# AE302F80F55D5LE_CM55_HE_View register map
Vendor: Alif Semiconductor; Series: E3; File version: 1.0
CPU: CM55 r1p0, selectable endian, MPU, FPU, double-precision FPU, DSP, VTOR, 8 interrupt priority bits, 1 SAU regions
Registers are 32-bit, read-write, reset 0x0 unless marked. A register's access mark holds for its fields unless they carry their own. Offsets are from the block's base; [hi:lo] are bit positions; 'fields as' and 'values as' point back to an identical list.

## SDMMC (part 2 of 2)
Base 0x48102000
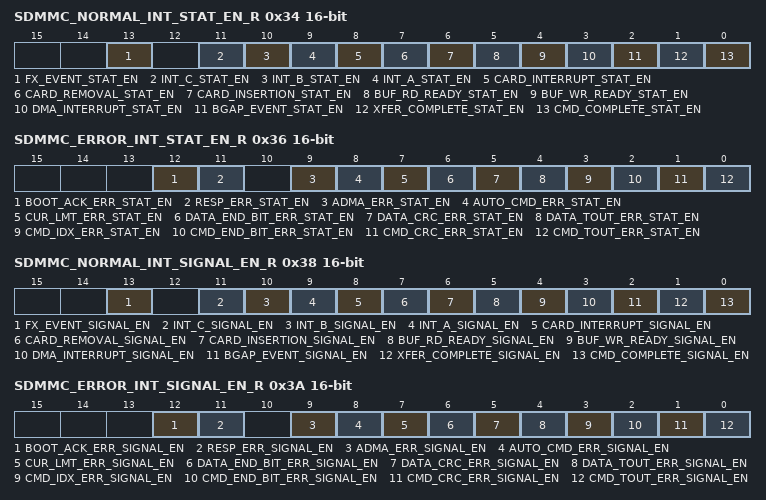
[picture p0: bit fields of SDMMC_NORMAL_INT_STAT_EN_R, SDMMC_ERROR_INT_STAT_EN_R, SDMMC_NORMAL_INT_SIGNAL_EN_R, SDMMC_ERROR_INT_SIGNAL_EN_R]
0x34 SDMMC_NORMAL_INT_STAT_EN_R 16-bit — Normal Interrupt Status Enable Register
  [all] fields
    0=Masked; 1=Enabled
  [13] FX_EVENT_STAT_EN — FX Event Status Enable. This bit is added from Version 4.10.
  [11] INT_C_STAT_EN — INT_C (Embedded) Status Enable. If this bit is set to 0x0, the Host Controller clears the interrupt request to the System. The Host Driver may clear this bit before servicing the INT_C and may set this bit again after all interrupt requests to INT_C pin are cleared to prevent inadvertent interrupts.
  [10] INT_B_STAT_EN — INT_B (Embedded) Status Enable. If this bit is set to 0x0, the Host Controller clears the interrupt request to the System. The Host Driver may clear this bit before servicing the INT_B and may set this bit again after all interrupt requests to INT_B pin are cleared to prevent inadvertent interrupts.
  [9] INT_A_STAT_EN — INT_A (Embedded) Status Enable. If this bit is set to 0x0, the Host Controller clears the interrupt request to the System. The Host Driver may clear this bit before servicing the INT_A and may set this bit again after all interrupt requests to INT_A pin are cleared to prevent inadvertent interrupts.
  [8] CARD_INTERRUPT_STAT_EN — Card Interrupt Status Enable. If this bit is set to 0x0, the Host Controller clears the interrupt request to the System. The Card Interrupt detection is stopped when this bit is cleared and restarted when this bit is set to 0x1. The Host Driver may clear the Card Interrupt Status Enable before servicing the Card Interrupt and may set this bit again after all interrupt requests from the card are cleared to prevent inadvertent interrupts. By setting this bit to 0x0, interrupt input must be masked by implementation so that the interrupt input is not affected by external signal in any state (for example: floating).
  [7] CARD_REMOVAL_STAT_EN — Card Removal Status Enable.
  [6] CARD_INSERTION_STAT_EN — Card Insertion Status Enable.
  [5] BUF_RD_READY_STAT_EN — Buffer Read Ready Status Enable.
  [4] BUF_WR_READY_STAT_EN — Buffer Write Ready Status Enable.
  [3] DMA_INTERRUPT_STAT_EN — DMA Interrupt Status Enable.
  [2] BGAP_EVENT_STAT_EN — Block Gap Event Status Enable.
  [1] XFER_COMPLETE_STAT_EN — Transfer Complete Status Enable.
  [0] CMD_COMPLETE_STAT_EN — Command Complete Status Enable.
0x36 SDMMC_ERROR_INT_STAT_EN_R 16-bit — Error Interrupt Status Enable Register
  [all] fields
    0=Masked; 1=Enabled
  [12] BOOT_ACK_ERR_STAT_EN — Boot Acknowledgment Error (eMMC mode only). Setting this bit to 0x1 enables setting of Boot Acknowledgment Error in the SDMMC_ERROR_INT_STAT_R register.
  [11] RESP_ERR_STAT_EN — Response Error Status Enable (SD mode only).
  [9] ADMA_ERR_STAT_EN — ADMA Error Status Enable.
  [8] AUTO_CMD_ERR_STAT_EN — Auto CMD Error Status Enable (SD or eMMC mode only).
  [7] CUR_LMT_ERR_STAT_EN — Current Limit Error Status Enable.
  [6] DATA_END_BIT_ERR_STAT_EN — Data End Bit Error Status Enable (SD or eMMC mode only).
  [5] DATA_CRC_ERR_STAT_EN — Data CRC Error Status Enable (SD or eMMC mode only).
  [4] DATA_TOUT_ERR_STAT_EN — Data Timeout Error Status Enable (SD or eMMC mode only).
  [3] CMD_IDX_ERR_STAT_EN — Command Index Error Status Enable (SD or eMMC mode only).
  [2] CMD_END_BIT_ERR_STAT_EN — Command End Bit Error Status Enable (SD or eMMC mode only).
  [1] CMD_CRC_ERR_STAT_EN — Command CRC Error Status Enable (SD or eMMC mode only).
  [0] CMD_TOUT_ERR_STAT_EN — Command Timeout Error Status Enable (SD or eMMC mode only).
0x38 SDMMC_NORMAL_INT_SIGNAL_EN_R 16-bit — Normal Interrupt Signal Enable Register
  [all] fields
    0=Masked; 1=Enabled
  [13] FX_EVENT_SIGNAL_EN — FX Event Signal Enable.
  [11] INT_C_SIGNAL_EN — INT_C (Embedded) Signal Enable.
  [10] INT_B_SIGNAL_EN — INT_B (Embedded) Signal Enable.
  [9] INT_A_SIGNAL_EN — INT_A (Embedded) Signal Enable.
  [8] CARD_INTERRUPT_SIGNAL_EN — Card Interrupt Signal Enable.
  [7] CARD_REMOVAL_SIGNAL_EN — Card Removal Signal Enable.
  [6] CARD_INSERTION_SIGNAL_EN — Card Insertion Signal Enable.
  [5] BUF_RD_READY_SIGNAL_EN — Buffer Read Ready Signal Enable.
  [4] BUF_WR_READY_SIGNAL_EN — Buffer Write Ready Signal Enable.
  [3] DMA_INTERRUPT_SIGNAL_EN — DMA Interrupt Signal Enable.
  [2] BGAP_EVENT_SIGNAL_EN — Block Gap Event Signal Enable.
  [1] XFER_COMPLETE_SIGNAL_EN — Transfer Complete Signal Enable.
  [0] CMD_COMPLETE_SIGNAL_EN — Command Complete Signal Enable.
0x3A SDMMC_ERROR_INT_SIGNAL_EN_R 16-bit — Error Interrupt Signal Enable Register
  [12] BOOT_ACK_ERR_SIGNAL_EN — Boot Acknowledgment Error (eMMC mode only). Setting this bit to 0x1 enables generating interrupt signal when Boot Acknowledgement Error in the SDMMC_ERROR_INT_STAT_R register is set.
    0=Masked; 1=Enabled
  [11] RESP_ERR_SIGNAL_EN — Response Error Signal Enable (SD mode only).
    0=Masked; 1=Enabled
  [9] ADMA_ERR_SIGNAL_EN — ADMA Error Signal Enable.
    0=Masked; 1=Enabled
  [8] AUTO_CMD_ERR_SIGNAL_EN — Auto CMD Error Signal Enable (SD or eMMC mode only).
    0=Masked; 1=Enabled
  [7] CUR_LMT_ERR_SIGNAL_EN — Current Limit Error Signal Enable.
    0=Masked; 1=Enabled
  [6] DATA_END_BIT_ERR_SIGNAL_EN — Data End Bit Error Signal Enable (SD or eMMC mode only).
    0=Masked; 1=Enabled
  [5] DATA_CRC_ERR_SIGNAL_EN — Data CRC Error Signal Enable (SD or eMMC mode only).
    0=Masked; 1=Enabled
  [4] DATA_TOUT_ERR_SIGNAL_EN — Data Timeout Error Signal Enable (SD or eMMC mode only).
    0=Masked; 1=Enabled
  [3] CMD_IDX_ERR_SIGNAL_EN — Command Index Error Signal Enable (SD or eMMC mode only).
    0=No error; 1=Error
  [2] CMD_END_BIT_ERR_SIGNAL_EN — Command End Bit Error Signal Enable (SD or eMMC mode only).
    0=Masked; 1=Enabled
  [1] CMD_CRC_ERR_SIGNAL_EN — Command CRC Error Signal Enable (SD or eMMC mode only).
    0=Masked; 1=Enabled
  [0] CMD_TOUT_ERR_SIGNAL_EN — Command Timeout Error Signal Enable (SD or eMMC mode only).
    0=Masked; 1=Enabled
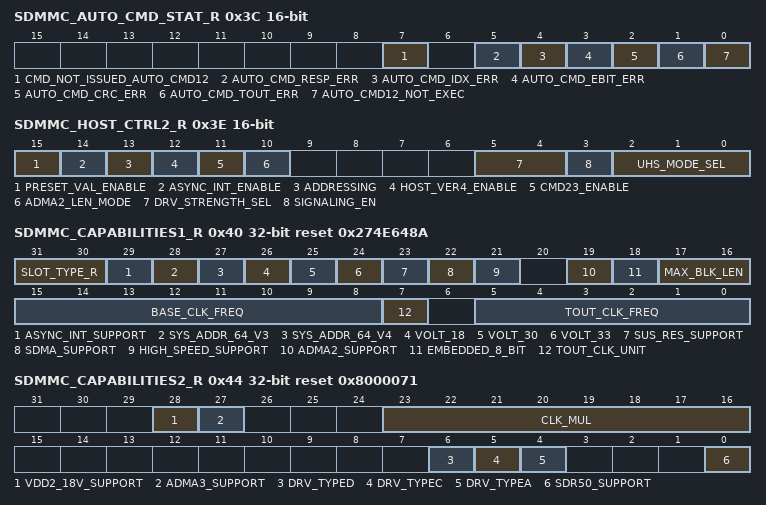
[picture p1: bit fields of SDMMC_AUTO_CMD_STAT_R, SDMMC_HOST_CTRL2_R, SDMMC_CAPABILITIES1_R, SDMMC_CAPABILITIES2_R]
0x3C SDMMC_AUTO_CMD_STAT_R 16-bit ro — Auto CMD Status Register
  [7] CMD_NOT_ISSUED_AUTO_CMD12 — Command Not Issued By Auto CMD12 Error. This bit is set to 0x0 when Auto CMD Error is generated by Auto CMD23.
    0=No error; 1=Not issued
  [5] AUTO_CMD_RESP_ERR — Auto CMD Response Error. This bit is set when the SDMMC_XFER_MODE_R[RESP_ERR_CHK_ENABLE] bit is set to 0x1 and an error is detected in R1 response of either Auto CMD12 or CMD13. This status is ignored if any bit between D00 to D04 is set to 0x1.
    0=No error; 1=Error
  [4] AUTO_CMD_IDX_ERR — Auto CMD Index Error. This bit is set if the command index error occurs in response to a command.
    0=No error; 1=Error
  [3] AUTO_CMD_EBIT_ERR — Auto CMD End Bit Error. This bit is set when detecting that the end bit of command response is 0x0.
    0=No error; 1=End bit error generated
  [2] AUTO_CMD_CRC_ERR — Auto CMD CRC Error. This bit is set when detecting a CRC error in the command response.
    0=No Error; 1=CRC Error Generated
  [1] AUTO_CMD_TOUT_ERR — Auto CMD Timeout Error. This bit is set if no response is returned with 64 SD_CLK cycles from the end bit of the command. If this bit is set to 0x1, error status bits (D04 to D01) are meaningless.
    0=No error; 1=Time out
  [0] AUTO_CMD12_NOT_EXEC — Auto CMD12 Not Executed. If multiple memory block data transfer is not started due to a command error, this bit is not set because it is not necessary to issue an Auto CMD12. Setting this bit to 0x1 means that the Host Controller cannot issue Auto CMD12 to stop multiple memory block data transfer, due to some error. If this bit is set to 0x1, error status bits (D04 to D01) is meaningless. This bit is set to 0x0 when Auto CMD Error is generated by Auto CMD23.
    0=Executed; 1=Not executed
0x3E SDMMC_HOST_CTRL2_R 16-bit — Host Control 2 Register
  [15] PRESET_VAL_ENABLE — Preset Value Enable. This bit enables automatic selection of SD_CLK frequency and Driver strength in Preset Value registers. When this bit is set, SD_CLK frequency generation (SDMMC_CLK_CTRL_R[CLK_GEN_SELECT], the SDMMC_CLK_CTRL_R[FREQ_SEL]), and the driver strength selection are performed by the Host Controller. These values are selected from set of Preset Value registers based on selected speed mode.
    0=SD_CLK and driver strength are controlled by Host Driver; 1=Automatic selection by preset value are enabled
  [14] ASYNC_INT_ENABLE — Asynchronous Interrupt Enable. This bit can be set if a card supports asynchronous interrupts and this bit is set to 0x1 in the Capabilities registers (SDMMC_CAPABILITIES1_R and SDMMC_CAPABILITIES2_R).
    0=Disabled; 1=Enabled
  [13] ADDRESSING — 64-bit Addressing. This bit is effective when the HOST_VER4_ENABLE bit is set to 0x1.
    0=32 bits addressing; 1=64 bits addressing
  [12] HOST_VER4_ENABLE — Host Version 4 Enable. This bit selects either Version 3.00 compatible mode or Version 4 mode. Functions of following fields are modified for Host Version 4 mode: - SDMA Address: SDMA uses the SDMMC_ADMA_SA_LOW_R register (0x58 - 0x5F) instead of the SDMMC_SDMASA_R register (0x0 - 0x3). - ADMA2/ADMA3 selection: ADMA3 is selected by the SDMMC_HOST_CTRL1_R[DMA_SEL] bit field. - 64-bit ADMA Descriptor Size: 128-bit descriptor is used instead of 96-bit descriptor when 64-bit Addressing is set to 0x1. - Selection of 32-bit/64-bit System Addressing: Either 32-bit or 64-bit system addressing is selected by 64-bit Addressing bit in this register. - 32-bit Block Count: The SDMMC_SDMASA_R register (0x0 - 0x3) is modified to 32-bit Block Count Register Note: It is recommended not to program ADMA3 Integrated Descriptor Address registers, while operating in Host version less than 4 mode (HOST_VER4_ENABLE = 0x0).
    0=Version 3.00 compatible mode; 1=Version 4 mode
  [11] CMD23_ENABLE — CMD23 Enable. If the card supports CMD23, this bit is set to 0x1. This bit is used to select Auto CMD23 or Auto CMD12 for ADMA3 data transfer.
    0=Auto CMD23 is disabled; 1=Auto CMD23 is enabled
  [10] ADMA2_LEN_MODE — ADMA2 Length Mode. This bit selects ADMA2 Length mode to be either 16-bit or 26-bit.
    0=16-bit Data Length mode; 1=26-bit Data Length mode
  [5:4] DRV_STRENGTH_SEL — Driver Strength Select. This bit is used to select the Host Controller output driver in 1.8 V signaling UHS-I or eMMC speed modes. The bit depends on setting of the PRESET_VAL_ENABLE bit.
    0=Driver TYPEB is selected; 1=Driver TYPEA is selected; 2=Driver TYPEC is selected; 3=Driver TYPED is selected
  [3] SIGNALING_EN — 1.8 V Signaling Enable. This bit controls voltage regulator for I/O cell in UHS-I or eMMC speed modes. Setting this bit from 0x0 to 0x1 starts changing the signal voltage from 3.3 V to 1.8 V. The Host Controller clears this bit if switching to 1.8 signaling fails. Note: This bit must be set for all UHS-I speed modes (SDR12/SDR25/SDR50).
    0=3.3 V signalling; 1=1.8 V signalling
  [2:0] UHS_MODE_SEL — UHS Mode or eMMC Speed Mode Select. These bits are used to select UHS mode in the SD mode of operation. In eMMC mode, these bits are used to select eMMC speed mode. UHS mode (SD mode only):
    0=SDR12; 1=SDR25; 2=SDR50
0x40 SDMMC_CAPABILITIES1_R ro reset 0x274E648A — Capabilities 1 Register (0 to 31)
  [31:30] SLOT_TYPE_R — Slot Type. These bits indicate usage of a slot by a specific Host System.
    0=Removable card slot; 1=Embedded slot for one device; 2=Shared bus slot (SD mode)
  [29] ASYNC_INT_SUPPORT — Asynchronous Interrupt Support (SD mode only).
    0=Asynchronous interrupt not supported; 1=Asynchronous interrupt supported
  [28] SYS_ADDR_64_V3 — 64-bit System Address Support for V3. This bit sets the Host controller to support 64-bit System Addressing of V3 mode. SDMA cannot be used in 64-bit Addressing in Version 3 Mode. If this bit is set to 0x1, 64-bit ADMA2 with using 96-bit Descriptor can be enabled by setting the SDMMC_HOST_CTRL2_R[HOST_VER4_ENABLE] bit to 0x0 and SDMMC_HOST_CTRL1_R[DMA_SEL] bit field to 0x3.
    0=64-bit System address for V3 not supported; 1=64-bit System address for V3 supported
  [27] SYS_ADDR_64_V4 — 64-bit System Address Support for V4. This bit sets the Host Controller to support 64-bit System Addressing of V4 mode. When this bit is set to 0x1, full or part of 64-bit address must be used to decode the Host Controller registers so that Host Controller registers can be placed above system memory area. 64-bit address decode of Host Controller registers is effective regardless of setting to 64-bit Addressing in the SDMMC_HOST_CTRL2_R register. If this bit is set to 0x1, 64-bit DMA Addressing for version 4 is enabled by setting the SDMMC_HOST_CTRL2_R[HOST_VER4_ENABLE] and SDMMC_HOST_CTRL2_R[ADDRESSING] bits to 0x1, SDMA can be used and ADMA2 uses 128-bit Descriptor.
    0=64-bit System address for V4 not supported; 1=64-bit System address for V4 supported
  [26] VOLT_18 — Voltage Support for 1.8 V.
    0=1.8 V not supported; 1=1.8 V supported
  [25] VOLT_30 — Voltage Support for SD 3.0 V or Embedded 1.2 V.
    0=SD 3.0 V or embedded 1.2 V not supported; 1=SD 3.0 V or embedded supported
  [24] VOLT_33 — Voltage Support for 3.3 V.
    0=3.3 V not supported; 1=3.3 V supported
  [23] SUS_RES_SUPPORT — Suspense/Resume Support. This bit indicates whether the Host Controller supports Suspend/Resume functionality. If this bit is 0x0, the Host Driver does not issue either Suspend or Resume commands because the Suspend and Resume mechanism is not supported.
    0=Not supported; 1=Supported
  [22] SDMA_SUPPORT — SDMA Support. This bit indicates whether the Host Controller is capable of using SDMA to transfer data between the system memory and the Host Controller directly.
    0=SDMA not supported; 1=SDMA supported
  [21] HIGH_SPEED_SUPPORT — High Speed Support. This bit indicates whether the Host Controller and the Host System supports High Speed mode and they can supply the SD Clock frequency from 25 MHz to 50 MHz.
    0=High speed not supported; 1=High speed supported
  [19] ADMA2_SUPPORT — ADMA2 Support. This bit indicates whether the Host Controller is capable of using ADMA2.
    0=ADMA2 not supported; 1=ADMA2 supported
  [18] EMBEDDED_8_BIT — 8-bit Support for Embedded Device. This bit indicates whether the Host Controller is capable of using an 8-bit bus width mode. This bit is not effective when the SLOT_TYPE_R bit is set to 0x2.
    0=8-bit bus width not supported; 1=8-bit bus width supported
  [17:16] MAX_BLK_LEN — Maximum Block Length. This bit indicates the maximum block size that the Host Driver can read and write to the buffer in the Host Controller. The buffer transfers this block size without wait cycles. The transfer block length is always 512 Bytes for the SD Memory irrespective of this bit.
    0=512 Bytes; 1=1024 Bytes; 2=2048 Bytes
  [15:8] BASE_CLK_FREQ — Base Clock Frequency for SD Clock. These bits indicate the base (maximum) clock frequency for the SD Clock. The definition of these bits depend on the Host Controller Version. 6-Bit Base Clock Frequency: This mode is supported by the Host Controller version 1.00 and 2.00. The upper 2 bits are not effective and are always 0x0. The unit values are 1 MHz. The supported clock range is 10 MHz to 63 MHz. 0x0: Get information through another method 0x1: 1 MHz 0x2: 2 MHz ... 0x3F: 63 MHz 0x40 - 0xFF: Not supported 8-Bit Base Clock Frequency: This mode is supported by the Host Controller version 3.00. The unit values are 1 MHz. The supported clock range is 10 MHz to 255 MHz. 0x0: Get information through another method 0x1: MHz 0x2: 2 MHz ... 0xFF: 255 MHz
  [7] TOUT_CLK_UNIT — Timeout Clock Unit. This bit shows the unit of base clock frequency used to detect Data Timeout Error.
    0=kHz; 1=MHz
  [5:0] TOUT_CLK_FREQ — Timeout Clock Frequency. This bit shows the base clock frequency used to detect Data Timeout Error. The Timeout Clock unit defines the unit of timeout clock frequency. It can be kHz or MHz.
    0=Get information through another method; 1=1 kHz / 1 MHz; 2=2 kHz / 2 MHz; 3=3 kHz / 3 MHz; 63=63 kHz / 63 MHz
0x44 SDMMC_CAPABILITIES2_R ro reset 0x8000071 — Capabilities 2 Register (32 to 63)
  [28] VDD2_18V_SUPPORT — 1.8 V VDD2 Support. This bit indicates support of VDD2 for the Host System.
    0=1.8 V VDD2 not supported; 1=1.8 V VDD2 supported
  [27] ADMA3_SUPPORT — ADMA3 Support. This bit indicates whether the Host Controller is capable of using ADMA3.
    0=ADMA3 not supported; 1=ADMA3 supported
  [23:16] CLK_MUL — Clock Multiplier. These bits indicate the clock multiplier of the programmable clock generator. Setting these bits to 0x0 means that the Host Controller does not support a programmable clock generator.
    0=Clock multiplier not supported; 1=Clock multiplier M = 2; 2=Clock multiplier M = 3; 255=Clock multiplier M = 256
  [6] DRV_TYPED — Driver Type D Support (UHS-I Only). This bit indicates support of Driver Type D for 1.8 V Signaling.
    0=Driver Type D not supported; 1=Driver Type D supported
  [5] DRV_TYPEC — Driver Type C Support (UHS-I Only). This bit indicates support of Driver Type C for 1.8 V Signaling.
    0=Driver Type C not supported; 1=Driver Type C supported
  [4] DRV_TYPEA — Driver Type A Support (UHS-I Only). This bit indicates support of Driver Type A for 1.8 V Signaling.
    0=Driver Type A not supported; 1=Driver Type A supported
  [0] SDR50_SUPPORT — SDR50 Support (UHS-I Only). This bit indicates that SDR50 is supported.
    0=SDR50 not supported; 1=SDR50 supported
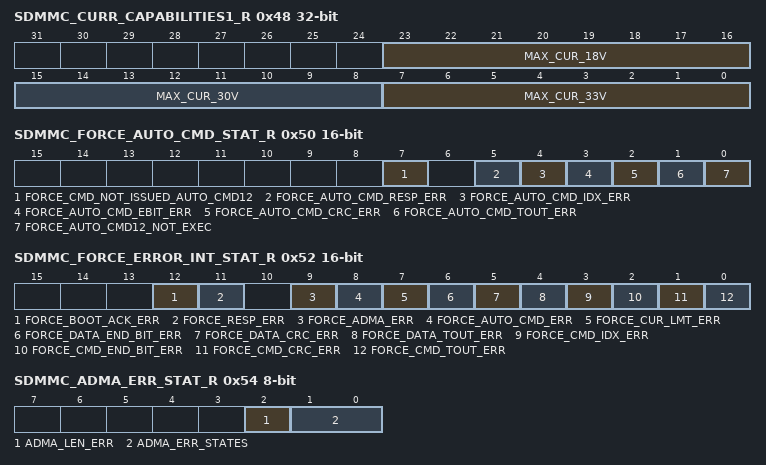
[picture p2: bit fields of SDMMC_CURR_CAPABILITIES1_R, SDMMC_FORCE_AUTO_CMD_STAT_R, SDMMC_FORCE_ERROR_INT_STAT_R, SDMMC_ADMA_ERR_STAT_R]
0x48 SDMMC_CURR_CAPABILITIES1_R ro — Maximum Current Capabilities 1 Register (0 to 31)
  [all] fields
    0=Get information through another method; 1=4 mA; 2=8 mA; 3=13 mA
  [23:16] MAX_CUR_18V — Maximum Current for 1.8 V. This bit specifies the card Maximum Current for 1.8 V VDD1 power supply. 0xFF 1020 mA
  [15:8] MAX_CUR_30V — Maximum Current for 3.0 V. This bit specifies the card Maximum Current for 3.0 V VDD1 power supply. 0xFF 1020 mA
  [7:0] MAX_CUR_33V — Maximum Current for 3.3 V. This bit specifies the card Maximum Current for 3.3 V VDD1 power supply. 0xFF 1020 mA
0x50 SDMMC_FORCE_AUTO_CMD_STAT_R 16-bit — Force Event Register for Auto CMD Error Status
  [7] FORCE_CMD_NOT_ISSUED_AUTO_CMD12 wo — Force Event for Command Not Issued By Auto CMD12 Error.
    0=Not affected; 1=Command Not Issued By Auto CMD12 Error Status is set
  [5] FORCE_AUTO_CMD_RESP_ERR wo — Force Event for Auto CMD Response Error.
    0=Not affected; 1=Auto CMD Response Error Status is set
  [4] FORCE_AUTO_CMD_IDX_ERR wo — Force Event for Auto CMD Index Error.
    0=Not affected; 1=Auto CMD Index Error Status is set
  [3] FORCE_AUTO_CMD_EBIT_ERR wo — Force Event for Auto CMD End Bit Error.
    0=Not affected; 1=Auto CMD End Bit Error Status is set
  [2] FORCE_AUTO_CMD_CRC_ERR wo — Force Event for Auto CMD CRC Error.
    0=Not affected; 1=Auto CMD CRC Error Status is set
  [1] FORCE_AUTO_CMD_TOUT_ERR wo — Force Event for Auto CMD Timeout Error.
    0=Not affected; 1=Auto CMD Timeout Error Status is set
  [0] FORCE_AUTO_CMD12_NOT_EXEC wo — Force Event for Auto CMD12 Not Executed.
    0=Not affected; 1=Auto CMD12 Not Executed Status is set
0x52 SDMMC_FORCE_ERROR_INT_STAT_R 16-bit wo — Force Event Register for Error Interrupt Status
  [12] FORCE_BOOT_ACK_ERR — Force Event for Boot ACK Error.
    0=Not affected; 1=Boot ACK Error Status is set
  [11] FORCE_RESP_ERR — Force Event for Response Error (SD mode only).
    0=Not affected; 1=Response Error Status is set
  [9] FORCE_ADMA_ERR — Force Event for ADMA Error.
    0=Not affected; 1=ADMA Error Status is set
  [8] FORCE_AUTO_CMD_ERR — Force Event for Auto CMD Error (SD and eMMC modes).
    0=Not affected; 1=Auto CMD Error Status is set
  [7] FORCE_CUR_LMT_ERR — Force Event for Current Limit Error.
    0=Not affected; 1=Current Limit Error Status is set
  [6] FORCE_DATA_END_BIT_ERR — Force Event for Data End Bit Error (SD and eMMC modes).
    0=Not affected; 1=Data End Bit Error Status is set
  [5] FORCE_DATA_CRC_ERR — Force Event for Data CRC Error (SD and eMMC modes).
    0=Not affected; 1=Data CRC Error Status is set
  [4] FORCE_DATA_TOUT_ERR — Force Event for Data Timeout Error (SD and eMMC modes).
    0=Not affected; 1=Data Timeout Error Status is set
  [3] FORCE_CMD_IDX_ERR — Force Event for Command Index Error (SD or eMMC modes).
    0=Not affected; 1=Command Index Error Status is set
  [2] FORCE_CMD_END_BIT_ERR — Force Event for Command End Bit Error (SD and eMMC modes).
    0=Not affected; 1=Command End Bit Error Status is set
  [1] FORCE_CMD_CRC_ERR — Force Event for Command CRC Error (SD and eMMC modes).
    0=Not affected; 1=Command CRC Error Status is set
  [0] FORCE_CMD_TOUT_ERR — Force Event for Command Timeout Error (SD and eMMC modes).
    0=Not affected; 1=Command Timeout Error Status is set
0x54 SDMMC_ADMA_ERR_STAT_R 8-bit ro — ADMA Error Status Register
  [2] ADMA_LEN_ERR — ADMA Length Mismatch Error States. This error occurs in the following events: - While the SDMMC_XFER_MODE_R[BLOCK_COUNT_ENABLE] bit is being set, the total data length specified by the Descriptor table is different from that specified by the Block Count and Block Length. - When the total data length cannot be divided by the block length.
    0=No error; 1=Error
  [1:0] ADMA_ERR_STATES — ADMA Error States. These bits indicate the state of ADMA when an error occurs during ADMA data transfer.
    0=Stop DMA (SYS_ADR register points to a location next to the error descriptor); 1=Fetch Descriptor (SYS_ADR register points to the error descriptor); 2=Never set this state; 3=Transfer Data (SYS_ADR register points to a location next to the error descriptor)
0x58 SDMMC_ADMA_SA_LOW_R — ADMA System Address Register (Low)
  [31:0] ADMA_SA_LOW — ADMA System Address. These bits indicate the lower 32 bits of the ADMA system address. SDMA: If the SDMMC_HOST_CTRL2_R[HOST_VER4_ENABLE] bit is set to 0x1, this register stores the system address of the data location. ADMA2: This register stores the byte address of the executing command of the descriptor table. ADMA3: This register is set by ADMA3. ADMA2 increments the address of this register that points to the next line, every time a Descriptor line is fetched.
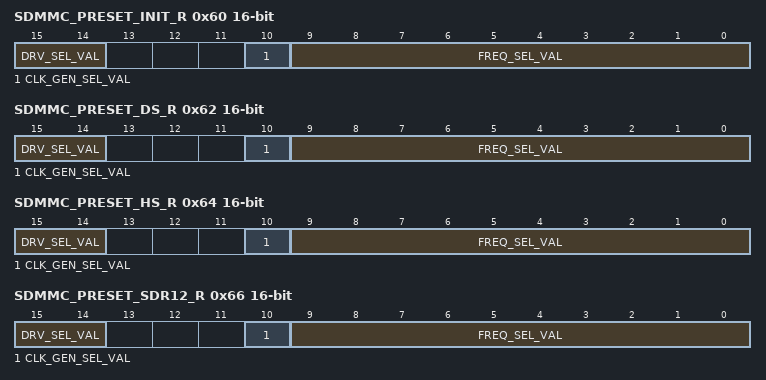
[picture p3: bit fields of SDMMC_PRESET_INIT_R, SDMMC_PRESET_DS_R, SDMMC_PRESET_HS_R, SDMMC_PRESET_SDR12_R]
0x60 SDMMC_PRESET_INIT_R 16-bit ro — Register with Preset Value for Initialization
  [15:14] DRV_SEL_VAL — Driver Strength Select Value. These bits indicate that the Driver strength is supported by 1.8 V signaling bus speed modes. These bits are meaningless for 3.3 V signaling.
    0=Driver Type B is selected; 1=Driver Type A is selected; 2=Driver Type C is selected; 3=Driver Type D is selected
  [10] CLK_GEN_SEL_VAL — Clock Generator Select Value. This bit is effective when the Host Controller supports a programmable clock generator.
    0=Host Controller Ver2.0 compatible clock generator; 1=Programmable clock generator
  [9:0] FREQ_SEL_VAL — SD_CLK Frequency Select Value. 10-bit preset value to be set in the SDMMC_CLK_CTRL_R[FREQ_SEL] bit field described by a Host System.
0x62 SDMMC_PRESET_DS_R 16-bit ro — Register with Preset Value for Default Speed
  [15:14] DRV_SEL_VAL — Driver Strength Select Value. These bits indicate the Driver strength value supported by 1.8 V signaling bus speed modes. This field is meaningless for the Default speed mode as it uses 3.3 V signaling.
    values as SDMMC_PRESET_INIT_R.DRV_SEL_VAL
  [10] CLK_GEN_SEL_VAL — Clock Generator Select Value. This bit is effective when the Host Controller supports programmable clock generator.
    values as SDMMC_PRESET_INIT_R.CLK_GEN_SEL_VAL
  [9:0] FREQ_SEL_VAL — SD_CLK Frequency Select Value. 10-bit preset value to be set in the SDMMC_CLK_CTRL_R[FREQ_SEL] bit field described by a Host System.
0x64 SDMMC_PRESET_HS_R 16-bit ro — Register with Preset Value for High Speed
  [15:14] DRV_SEL_VAL — Driver Strength Select Value. These bits indicate the Driver strength value supported by 1.8 V signaling bus speed modes. This field is meaningless for High speed mode as it uses 3.3 V signaling.
    values as SDMMC_PRESET_INIT_R.DRV_SEL_VAL
  [10] CLK_GEN_SEL_VAL — Clock Generator Select Value. This bit is effective when the Host Controller supports programmable clock generator.
    values as SDMMC_PRESET_INIT_R.CLK_GEN_SEL_VAL
  [9:0] FREQ_SEL_VAL — SD_CLK Frequency Select Value. 10-bit preset value to be set in the SDMMC_CLK_CTRL_R[FREQ_SEL] bit field described by a Host System.
0x66 SDMMC_PRESET_SDR12_R 16-bit ro — Register with Preset Value for SDR12
  [15:14] DRV_SEL_VAL — Driver Strength Select Value. These bits indicate the Driver strength value supported for the SDR12 bus speed mode. These bits are meaningless for 3.3 V signaling.
    values as SDMMC_PRESET_INIT_R.DRV_SEL_VAL
  [10] CLK_GEN_SEL_VAL — Clock Generator Select Value. This bit is effective when the Host Controller supports programmable clock generator.
    values as SDMMC_PRESET_INIT_R.CLK_GEN_SEL_VAL
  [9:0] FREQ_SEL_VAL — SD_CLK Frequency Select Value. 10-bit preset value to be set in the SDMMC_CLK_CTRL_R[FREQ_SEL] bit field described by a Host System.
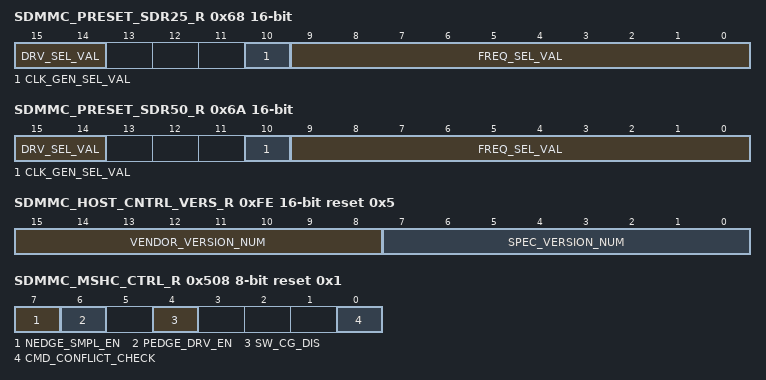
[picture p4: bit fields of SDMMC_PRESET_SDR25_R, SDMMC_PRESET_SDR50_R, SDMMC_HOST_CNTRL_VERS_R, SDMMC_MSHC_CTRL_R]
0x68 SDMMC_PRESET_SDR25_R 16-bit ro — Register with Preset Value for SDR25
  [15:14] DRV_SEL_VAL — Driver Strength Select Value. These bits indicate the Driver strength value supported for the SDR25 bus speed mode. These bits are meaningless for 3.3 V signaling.
    values as SDMMC_PRESET_INIT_R.DRV_SEL_VAL
  [10] CLK_GEN_SEL_VAL — Clock Generator Select Value. This bit is effective when the Host Controller supports programmable clock generator.
    values as SDMMC_PRESET_INIT_R.CLK_GEN_SEL_VAL
  [9:0] FREQ_SEL_VAL — SD_CLK Frequency Select Value. 10-bit preset value to be set in the SDMMC_CLK_CTRL_R[FREQ_SEL] bit field described by a Host System.
0x6A SDMMC_PRESET_SDR50_R 16-bit ro — Register with Preset Value for SDR50
  [15:14] DRV_SEL_VAL — Driver Strength Select Value. These bits indicate Driver strength value supported for SDR50 bus speed mode. These bits are meaningless for 3.3 V signaling.
    values as SDMMC_PRESET_INIT_R.DRV_SEL_VAL
  [10] CLK_GEN_SEL_VAL — Clock Generator Select Value. This bit is effective when the Host Controller supports programmable clock generator.
    values as SDMMC_PRESET_INIT_R.CLK_GEN_SEL_VAL
  [9:0] FREQ_SEL_VAL — SD_CLK Frequency Select Value. 10-bit preset value to be set in the SDMMC_CLK_CTRL_R[FREQ_SEL] bit field described by a Host System.
0x78 SDMMC_ADMA_ID_LOW_R — ADMA3 Integrated Descriptor Address Register (Low)
  [31:0] ADMA_ID_LOW — ADMA Integrated Descriptor Address. These bits indicate the lower 32-bit of the ADMA Integrated Descriptor Address. The start address of Integrated Descriptor is set to these register bits. The ADMA3 fetches one Integrated Descriptor Address and increments these bits to indicate the next Integrated Descriptor Address.
0xE8 SDMMC_P_VENDOR_SPECIFIC_AREA 16-bit ro reset 0x500 — Pointer for Vendor Specific Area 1
  [11:0] REG_OFFSET_ADDR — Base offset Address for Vendor Specific registers.
0xFC SDMMC_SLOT_INTR_STATUS_R 16-bit ro — Slot Interrupt Status Register
  [7:0] INTR_SLOT — Interrupt Signal for each Slot. These status bits indicate the logical OR of interrupt signal and wakeup signal for each slot. A maximum of 8 slots can be defined. If one interrupt signal is associated with multiple slots, the Host Driver can identify the interrupt that is generated by reading these bits. By a power on reset or by setting the SDMMC_SW_RST_R[SW_RST_ALL] bit, the interrupt signals are de-asserted and this status reads 0x0. Bit 00: Slot 1 Bit 01: Slot 2 Bit 02: Slot 3 Bit 07: Slot 8
0xFE SDMMC_HOST_CNTRL_VERS_R 16-bit ro reset 0x5 — Host Controller Version Register
  [15:8] VENDOR_VERSION_NUM — Vendor version number
  [7:0] SPEC_VERSION_NUM — Host controller specification version number
0x500 SDMMC_MSHC_VER_ID_R ro reset 0x3138302A — MSHC Version ID Register
  [31:0] MSHC_VER_ID — Current release number
0x504 SDMMC_MSHC_VER_TYPE_R ro reset 0x67612A2A — MSHC Version Type Register
  [31:0] MSHC_VER_TYPE — Current release type
0x508 SDMMC_MSHC_CTRL_R 8-bit reset 0x1 — SDMMC Host Controller Control Register
  [7] NEDGE_SMPL_EN — Samples CMD/DATA with respect to negative edge of CCLK_RX for Low-Speed SDR only support.
    0=Samples CMD/DATA with respect to positive edge of CCLK_RX; 1=Samples CMD/DATA with respect to negative edge of CCLK_RX
  [6] PEDGE_DRV_EN — Launches CMD/DATA with respect to positive edge of CCLK_TX for Low-Speed SDR only support.
    0=Launches CMD/DATA with respect to negative edge of CCLK_TX; 1=Launches CMD/DATA with respect to positive edge of CCLK_TX
  [4] SW_CG_DIS — Internal Clock Gating Disable Control. This bit must be used to disable the SDMMC module internal clock gating when required (disabled clocks are not gated). The clocks to the core (except HCLK) must be stopped when programming this bit.
    0=Internal clock gates are active and clock gating is controlled internally; 1=Internal clock gating is disabled, clocks are not gated internally
  [0] CMD_CONFLICT_CHECK — Command Conflict Check. This bit enables command conflict check.
    0=Disable command conflict check; 1=Check for command conflict after 1 card clock cycle
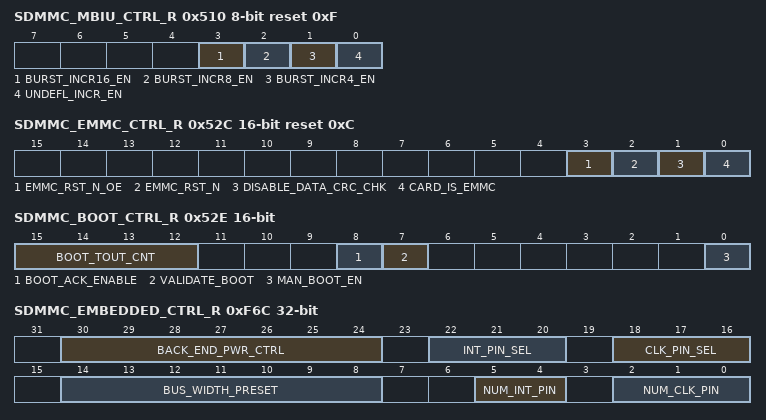
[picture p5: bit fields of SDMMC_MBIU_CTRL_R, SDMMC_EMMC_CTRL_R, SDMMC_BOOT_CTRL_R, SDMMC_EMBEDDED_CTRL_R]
0x510 SDMMC_MBIU_CTRL_R 8-bit reset 0xF — Master Bus Interface Unit Control Register
  [3] BURST_INCR16_EN — INCR16 Burst. Controls generation of INCR16 transfers on Master interface.
    0=AHB INCR16 burst type is not generated on Master interface; 1=AHB INCR16 burst type can be generated on Master interface
  [2] BURST_INCR8_EN — INCR8 Burst. Controls generation of INCR8 transfers on Master interface.
    0=AHB INCR8 burst type is not generated on Master interface; 1=AHB INCR8 burst type can be generated on Master interface
  [1] BURST_INCR4_EN — INCR4 Burst. Controls generation of INCR4 transfers on Master interface.
    0=AHB INCR4 burst type is not generated on Master interface; 1=AHB INCR4 burst type can be generated on Master interface
  [0] UNDEFL_INCR_EN — Undefined INCR Burst. Controls generation of undefined length INCR transfer on Master interface.
    0=Undefined INCR type burst is the least preferred burst on AHB Master interface; 1=Undefined INCR type burst is the most preferred burst on AHB Master interface
0x52C SDMMC_EMMC_CTRL_R 16-bit reset 0xC — eMMC Control Register
  [3] EMMC_RST_N_OE — Output Enable Control for eMMC Device Reset Signal PAD Control. This field drives SD_RST output of the SDMMC module.
    0=SD_RST is 0x0; 1=SD_RST is 0x1
  [2] EMMC_RST_N — eMMC Device Reset Signal Control. This register field controls SD_RST output of the SDMMC module.
    0=Reset to eMMC device asserted (active low); 1=Reset to eMMC device is de-asserted
  [1] DISABLE_DATA_CRC_CHK — Disable Data CRC Check. This bit controls masking of CRC16 error for Card Write in eMMC mode. This is useful in bus testing (CMD19) for an eMMC device. In bus testing, an eMMC card does not send CRC status for a block, which may generate CRC error. This CRC error can be masked using this bit during bus testing.
    0=DATA CRC check is enabled; 1=DATA CRC check is disabled
  [0] CARD_IS_EMMC — eMMC Card Present. This bit indicates the type of card connected. An application program this bit based on the card connected to the SDMMC Host Controller.
    0=Card connected to the SDMMC Host Controller is a non-eMMC card; 1=Card connected to the SDMMC Host Controller is an eMMC card
0x52E SDMMC_BOOT_CTRL_R 16-bit — eMMC Boot Control Register
  [15:12] BOOT_TOUT_CNT — Boot ACK Timeout Counter Value. This value determines the interval by which boot ACK timeout (50 ms) is detected when boot ACK is expected during boot operation.
    0=TMCLK x 2^13; 1=TMCLK x 2^14; 14=TMCLK x 2^27
  [8] BOOT_ACK_ENABLE — Boot Acknowledge Enable. When this bit set, the SDMMC module checks for boot acknowledge start pattern of 0-1-0 during boot operation. This bit is applicable for both mandatory and alternate boot mode.
    0=Boot ACK disable; 1=Boot ACK enable
  [7] VALIDATE_BOOT wo — Validate Mandatory Boot Enable Bit. This bit is used to validate the SDMMC_BOOT_CTRL_R[MAN_BOOT_EN] bit.
    0=Ignore mandatory boot enable bit; 1=Validate mandatory boot enable bit
  [0] MAN_BOOT_EN — Mandatory Boot Enable. This bit is used to initiate the mandatory boot operation. The application sets this bit along with the SDMMC_BOOT_CTRL_R[VALIDATE_BOOT] bit. Writing 0x0 is ignored. The SDMMC module clears this bit after the boot transfer is completed or terminated.
    0=Mandatory boot disable; 1=Mandatory boot enable
0xF6C SDMMC_EMBEDDED_CTRL_R — Embedded Control Register
  [30:24] BACK_END_PWR_CTRL — Back-End Power Control (SD Mode). Each bit of this bit field controls back-end power supply for an embedded device. Bit 24: Back-End Power for Device 1 Bit 25: Back-End Power for Device 2 Bit 26: Back-End Power for Device 3 Bit 27: Back-End Power for Device 4 Bit 28: Back-End Power for Device 5 Bit 29: Back-End Power for Device 6 Bit 30: Back-End Power for Device 7 Function of each bit is defined as follows:
    0=Back-End Power is off; 1=Back-End Power is supplied
  [22:20] INT_PIN_SEL — Interrupt Pin Select. These bits enable the interrupt pin inputs.
    0=Val_0b000 (Interrupts (INT_A, INT_B, INT_C) are disabled); 1=Val_0b001 (INT_A is enabled); 2=Val_0b010 (INT_B is enabled); 4=Val_0b100 (INT_C is enabled)
  [18:16] CLK_PIN_SEL — Clock Pin Select (SD Mode). This bit is selected by one of clock pin outputs.
    0=Clock pins are disabled; 1=CLK[1] is selected; 2=CLK[2] is selected; 7=CLK[7] is selected
  [14:8] BUS_WIDTH_PRESET ro — Bus Width Preset (SD Mode). Each bit of this field specifies the bus width for each embedded device. The shared bus supports mixing of 4-bit and 8-bit bus width devices. Bit 8: Bus Width Preset for Device 1 Bit 9: Bus Width Preset for Device 2 Bit 10: Bus Width Preset for Device 3 Bit 11: Bus Width Preset for Device 4 Bit 12: Bus Width Preset for Device 5 Bit 13: Bus Width Preset for Device 6 Bit 14: Bus Width Preset for Device 7 Function of each bit is defined as follows:
    0=4-bit bus width mode; 1=8-bit bus width mode
  [5:4] NUM_INT_PIN ro — Number of Interrupt Input Pins. This field indicates support of interrupt input pins for an embedded system.
  [2:0] NUM_CLK_PIN ro — Number of Clock Pins (SD Mode). This field indicates support of clock pins to select one of devices for shared bus system. Up to 7 clock pins can be supported.
    0=Shared bus not supported; 1=1 SD_CLK supported; 2=2 SD_CLK supported; 7=7 SD_CLK supported
